# ATmega64HVE2 device description
Architecture: AVR8; Family: megaAVR
Registers are 8-bit, access not given, no defined reset value unless marked. A register's access mark holds for its fields unless they carry their own. Offsets are from the block's base; [hi:lo] are bit positions.

## LOCKBIT — Lockbits
Instances: LOCKBIT 0 in lockbits
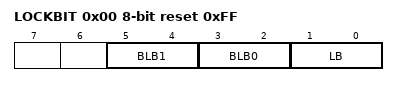
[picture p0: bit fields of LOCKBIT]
0x00 LOCKBIT reset 0xFF
  [5:4] BLB1 — Boot Loader Protection Mode
    0=LPM_SPM_DISABLE (LPM and SPM prohibited in Boot Section); 1=LPM_DISABLE (LPM prohibited in Boot Section); 2=SPM_DISABLE (SPM prohibited in Boot Section); 3=NO_LOCK (No lock on SPM and LPM in Boot Section)
  [3:2] BLB0 — Boot Loader Protection Mode
    0=LPM_SPM_DISABLE (LPM and SPM prohibited in Application Section); 1=LPM_DISABLE (LPM prohibited in Application Section); 2=SPM_DISABLE (SPM prohibited in Application Section); 3=NO_LOCK (No lock on SPM and LPM in Application Section)
  [1:0] LB — Memory Lock
    0=PROG_VER_DISABLED (Further programming and verification disabled); 2=PROG_DISABLED (Further programming disabled); 3=NO_LOCK (No memory lock features enabled)

## SPI — Serial Peripheral Interface
Instances: SPI 0x00
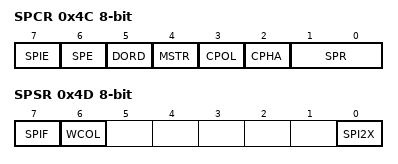
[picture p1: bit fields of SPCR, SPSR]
0x4C SPCR — SPI Control Register
  [7] SPIE — SPI Interrupt Enable
  [6] SPE — SPI Enable
  [5] DORD — Data Order
  [4] MSTR — Master/Slave Select
  [3] CPOL — Clock polarity
  [2] CPHA — Clock Phase
  [1:0] SPR — SPI Clock Rate Selects
    0=fosc/4; 1=fosc/16; 2=fosc/64; 3=fosc/128; 4=fosc/2; 5=fosc/8; 6=fosc/32; 7=fosc/64
0x4D SPSR — SPI Status Register
  [7] SPIF — SPI Interrupt Flag
  [6] WCOL — Write Collision Flag
  [0] SPI2X — Double SPI Speed Bit
0x4E SPDR — SPI Data Register

## EEPROM
Instances: EEPROM 0x00
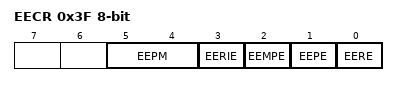
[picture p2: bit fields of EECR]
0x3F EECR — EEPROM Control Register
  [5:4] EEPM
    0=Erase and Write in one operation; 1=Erase Only; 2=Write Only
  [3] EERIE — EEProm Ready Interrupt Enable
  [2] EEMPE — EEPROM Master Write Enable
  [1] EEPE — EEPROM Write Enable
  [0] EERE — EEPROM Read Enable
0x40 EEDR — EEPROM Data Register
0x41 EEAR 16-bit bits used 9:0 — EEPROM Read/Write Access

## TC1 (TC16 module) — Timer/Counter, 16-bit
Instances: TC1 0x00
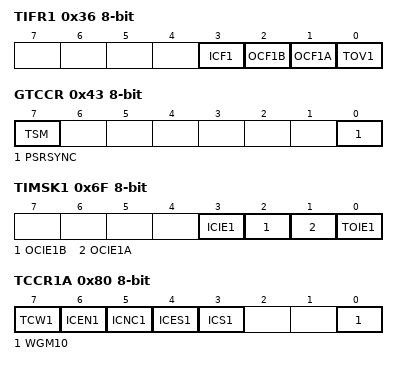
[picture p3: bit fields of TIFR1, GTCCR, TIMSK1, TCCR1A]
0x36 TIFR1 — Timer/Counter Interrupt Flag register
  [3] ICF1 — Timer/Counter 1 Input Capture Flag
  [2] OCF1B — Timer/Counter1 Output Compare Flag B
  [1] OCF1A — Timer/Counter1 Output Compare Flag A
  [0] TOV1 — Timer/Counter1 Overflow Flag
0x43 GTCCR — General Timer/Counter Control Register
  [7] TSM — Timer/Counter Synchronization Mode
  [0] PSRSYNC — Prescaler Reset
0x6F TIMSK1 — Timer/Counter Interrupt Mask Register
  [3] ICIE1 — Timer/Counter n Input Capture Interrupt Enable
  [2] OCIE1B — Timer/Counter1 Output Compare B Interrupt Enable
  [1] OCIE1A — Timer/Counter1 Output Compare A Interrupt Enable
  [0] TOIE1 — Timer/Counter1 Overflow Interrupt Enable
0x80 TCCR1A — Timer/Counter 1 Control Register A
  [7] TCW1 — Timer/Counter Width
  [6] ICEN1 — Input Capture Mode Enable
  [5] ICNC1 — Input Capture Noise Canceler
  [4] ICES1 — Input Capture Edge Select
  [3] ICS1 — Input Capture Select
  [0] WGM10 — Waveform Generation Mode
0x81 TCCR1B — Timer/Counter1 Control Register B
  [2:0] CS (bit 10 of the value upward) — Clock Select1 bis
    0=No Clock Source (Stopped); 1=Running, No Prescaling; 2=Running, CLK/8; 3=Running, CLK/64; 4=Running, CLK/256; 5=Running, CLK/1024; 6=Running, ExtClk Tx Falling Edge; 7=Running, ExtClk Tx Rising Edge
0x84 TCNT1 16-bit — Timer Counter 1 Bytes
0x88 OCR1A — Output Compare Register 1A
0x89 OCR1B — Output Compare Register B

## TC0 (TC16 module) — Timer/Counter, 16-bit
Instances: TC0 0x00
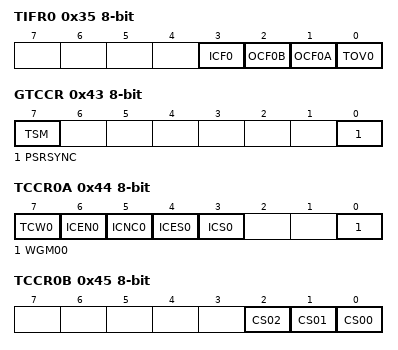
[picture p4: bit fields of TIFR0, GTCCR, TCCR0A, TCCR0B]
0x35 TIFR0 — Timer/Counter Interrupt Flag register
  [3] ICF0 — Timer/Counter 0 Input Capture Flag
  [2] OCF0B — Timer/Counter0 Output Compare Flag B
  [1] OCF0A — Timer/Counter0 Output Compare Flag A
  [0] TOV0 — Timer/Counter0 Overflow Flag
0x43 GTCCR — General Timer/Counter Control Register
  [7] TSM — Timer/Counter Synchronization Mode
  [0] PSRSYNC — Prescaler Reset
0x44 TCCR0A — Timer/Counter 0 Control Register A
  [7] TCW0 — Timer/Counter Width
  [6] ICEN0 — Input Capture Mode Enable
  [5] ICNC0 — Input Capture Noise Canceler
  [4] ICES0 — Input Capture Edge Select
  [3] ICS0 — Input Capture Select
  [0] WGM00 — Waveform Generation Mode
0x45 TCCR0B — Timer/Counter0 Control Register B
  [2] CS02 — Clock Select0 bit 2
  [1] CS01 — Clock Select0 bit 1
  [0] CS00 — Clock Select0 bit 0
    0=No Clock Source (Stopped); 1=Running, No Prescaling; 2=Running, CLK/8; 3=Running, CLK/64; 4=Running, CLK/256; 5=Running, CLK/1024; 6=Running, ExtClk Tx Falling Edge; 7=Running, ExtClk Tx Rising Edge
0x46 TCNT0 16-bit — Timer Counter 0 Bytes
0x48 OCR0A — Output Compare Register 0A
0x49 OCR0B — Output Compare Register B
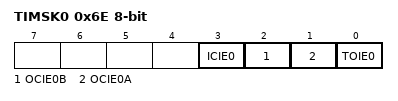
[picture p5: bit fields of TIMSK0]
0x6E TIMSK0 — Timer/Counter Interrupt Mask Register
  [3] ICIE0 — Timer/Counter n Input Capture Interrupt Enable
  [2] OCIE0B — Timer/Counter0 Output Compare B Interrupt Enable
  [1] OCIE0A — Timer/Counter0 Output Compare A Interrupt Enable
  [0] TOIE0 — Timer/Counter0 Overflow Interrupt Enable
